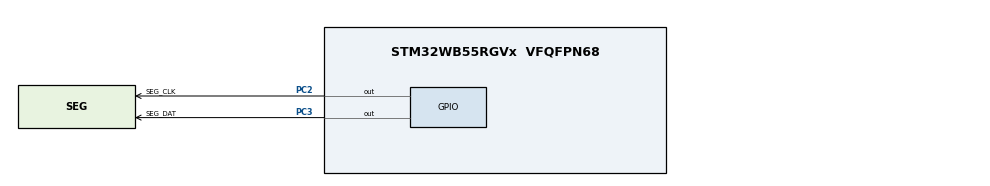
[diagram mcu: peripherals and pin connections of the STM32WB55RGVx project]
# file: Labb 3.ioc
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Mcu.Family=STM32WB
PC2.Signal=GPIO_Output
PC2.GPIO_Speed=GPIO_SPEED_FREQ_VERY_HIGH
PC3.GPIO_Speed=GPIO_SPEED_FREQ_VERY_HIGH
ProjectManager.StackSize=0x400
PC3.PinState=GPIO_PIN_SET
TIM1.Prescaler=1000
ProjectManager.TargetToolchain=STM32CubeIDE
PC3.Signal=GPIO_Output
RCC.LSE_VALUE=32768
RCC.HSE_VALUE=8000000
board=custom
RCC.VCOOutputFreq_Value=32000000
PC2.GPIO_PuPd=GPIO_PULLUP
Mcu.Name=STM32WB55RGVx
VP_TIM1_VS_ClockSourceINT.Mode=Internal
RCC.APB3Freq_Value=16000000
Mcu.Package=VFQFPN68
PC2.PinState=GPIO_PIN_SET
ProjectManager.HeapSize=0x200
RCC.HSI_VALUE=16000000
NVIC.TIM1_UP_TIM16_IRQn=true\:0\:0\:false\:false\:true\:true\:true
NVIC.PriorityGroup=NVIC_PRIORITYGROUP_4
PC2.GPIO_ModeDefaultOutputPP=GPIO_MODE_OUTPUT_OD
PC3.GPIO_Label=SEG_DAT
TIM1.Period=3200
PC3.GPIO_ModeDefaultOutputPP=GPIO_MODE_OUTPUT_OD
PC2.GPIO_Label=SEG_CLK
RCC.HSI48_VALUE=48000000
PC3.GPIO_PuPd=GPIO_PULLUP

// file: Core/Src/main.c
/* USER CODE BEGIN Header */
/**
 ******************************************************************************
 * @file           : main.c
 * @brief          : Main program body
 ******************************************************************************
 * @attention
 *
 * <h2><center>&copy; Copyright (c) 2021 STMicroelectronics.
 * All rights reserved.</center></h2>
 *
 * This software component is licensed by ST under BSD 3-Clause license,
 * the "License"; You may not use this file except in compliance with the
 * License. You may obtain a copy of the License at:
 *                        opensource.org/licenses/BSD-3-Clause
 *
 ******************************************************************************
 */
/* USER CODE END Header */
#include "main.h"
#include "SevenSeg.h"

TIM_HandleTypeDef htim1;

/* USER CODE BEGIN PV */
static int sec1;
static int sec10;
static int min1;
static int min10;
/* USER CODE END PV */

void SystemClock_Config(void);
static void MX_GPIO_Init(void);
static void MX_TIM1_Init(void);

/* USER CODE BEGIN 0 */

void HAL_TIM_PeriodElapsedCallback(TIM_HandleTypeDef *htim){
	if(htim->Instance==TIM1){
		if(++sec1>9){
			sec1=0;
			sec10++;
		}
		if(sec10 > 5){
			min1++;
			sec10 = 0;
		}
		if(min1 > 9)
		{
			min10++;
			min1=0;
		}
		if(min10>5)
			min10=0;

	}

}
/* USER CODE END 0 */

int main(void)
{

  /* MCU Configuration--------------------------------------------------------*/

  /* Reset of all peripherals, Initializes the Flash interface and the Systick. */
  HAL_Init();

  /* Configure the system clock */
  SystemClock_Config();

  /* Initialize all configured peripherals */
  MX_GPIO_Init();
  MX_TIM1_Init();
  /* USER CODE BEGIN 2 */
	HAL_TIM_Base_Start_IT(&htim1);
  /* USER CODE END 2 */

  /* Infinite loop */
  /* USER CODE BEGIN WHILE */
	while (1)
	{
		DisplayDigits(2,4,5,6,1);
		//DisplayDigits(min10, min1, sec10, sec1, sec1%2==0);
    /* USER CODE END WHILE */

	}
}

void SystemClock_Config(void)
{
  RCC_OscInitTypeDef RCC_OscInitStruct = {0};
  RCC_ClkInitTypeDef RCC_ClkInitStruct = {0};
  RCC_PeriphCLKInitTypeDef PeriphClkInitStruct = {0};

  /** Configure the main internal regulator output voltage
  */
  __HAL_PWR_VOLTAGESCALING_CONFIG(PWR_REGULATOR_VOLTAGE_SCALE1);
  /** Initializes the RCC Oscillators according to the specified parameters
  * in the RCC_OscInitTypeDef structure.
  */
  RCC_OscInitStruct.OscillatorType = RCC_OSCILLATORTYPE_HSI|RCC_OSCILLATORTYPE_MSI;
  RCC_OscInitStruct.HSIState = RCC_HSI_ON;
  RCC_OscInitStruct.MSIState = RCC_MSI_ON;
  RCC_OscInitStruct.HSICalibrationValue = RCC_HSICALIBRATION_DEFAULT;
  RCC_OscInitStruct.MSICalibrationValue = RCC_MSICALIBRATION_DEFAULT;
  RCC_OscInitStruct.MSIClockRange = RCC_MSIRANGE_6;
  RCC_OscInitStruct.PLL.PLLState = RCC_PLL_NONE;
  if (HAL_RCC_OscConfig(&RCC_OscInitStruct) != HAL_OK)
  {
    Error_Handler();
  }
  /** Configure the SYSCLKSource, HCLK, PCLK1 and PCLK2 clocks dividers
  */
  RCC_ClkInitStruct.ClockType = RCC_CLOCKTYPE_HCLK4|RCC_CLOCKTYPE_HCLK2
                              |RCC_CLOCKTYPE_HCLK|RCC_CLOCKTYPE_SYSCLK
                              |RCC_CLOCKTYPE_PCLK1|RCC_CLOCKTYPE_PCLK2;
  RCC_ClkInitStruct.SYSCLKSource = RCC_SYSCLKSOURCE_MSI;
  RCC_ClkInitStruct.AHBCLKDivider = RCC_SYSCLK_DIV1;
  RCC_ClkInitStruct.APB1CLKDivider = RCC_HCLK_DIV1;
  RCC_ClkInitStruct.APB2CLKDivider = RCC_HCLK_DIV1;
  RCC_ClkInitStruct.AHBCLK2Divider = RCC_SYSCLK_DIV1;
  RCC_ClkInitStruct.AHBCLK4Divider = RCC_SYSCLK_DIV1;

  if (HAL_RCC_ClockConfig(&RCC_ClkInitStruct, FLASH_LATENCY_0) != HAL_OK)
  {
    Error_Handler();
  }
  /** Initializes the peripherals clocks
  */
  PeriphClkInitStruct.PeriphClockSelection = RCC_PERIPHCLK_SMPS;
  PeriphClkInitStruct.SmpsClockSelection = RCC_SMPSCLKSOURCE_HSI;
  PeriphClkInitStruct.SmpsDivSelection = RCC_SMPSCLKDIV_RANGE1;
  if (HAL_RCCEx_PeriphCLKConfig(&PeriphClkInitStruct) != HAL_OK)
  {
    Error_Handler();
  }
}

static void MX_TIM1_Init(void)
{

  TIM_ClockConfigTypeDef sClockSourceConfig = {0};
  TIM_MasterConfigTypeDef sMasterConfig = {0};

  htim1.Instance = TIM1;
  htim1.Init.Prescaler = 1000;
  htim1.Init.CounterMode = TIM_COUNTERMODE_UP;
  htim1.Init.Period = 3200;
  htim1.Init.ClockDivision = TIM_CLOCKDIVISION_DIV1;
  htim1.Init.RepetitionCounter = 0;
  htim1.Init.AutoReloadPreload = TIM_AUTORELOAD_PRELOAD_DISABLE;
  if (HAL_TIM_Base_Init(&htim1) != HAL_OK)
  {
    Error_Handler();
  }
  sClockSourceConfig.ClockSource = TIM_CLOCKSOURCE_INTERNAL;
  if (HAL_TIM_ConfigClockSource(&htim1, &sClockSourceConfig) != HAL_OK)
  {
    Error_Handler();
  }
  sMasterConfig.MasterOutputTrigger = TIM_TRGO_RESET;
  sMasterConfig.MasterOutputTrigger2 = TIM_TRGO2_RESET;
  sMasterConfig.MasterSlaveMode = TIM_MASTERSLAVEMODE_DISABLE;
  if (HAL_TIMEx_MasterConfigSynchronization(&htim1, &sMasterConfig) != HAL_OK)
  {
    Error_Handler();
  }

}

static void MX_GPIO_Init(void)
{
  GPIO_InitTypeDef GPIO_InitStruct = {0};

  /* GPIO Ports Clock Enable */
  __HAL_RCC_GPIOC_CLK_ENABLE();

  /*Configure GPIO pin Output Level */
  HAL_GPIO_WritePin(GPIOC, SEG_CLK_Pin|SEG_DAT_Pin, GPIO_PIN_SET);

  /*Configure GPIO pins : SEG_CLK_Pin SEG_DAT_Pin */
  GPIO_InitStruct.Pin = SEG_CLK_Pin|SEG_DAT_Pin;
  GPIO_InitStruct.Mode = GPIO_MODE_OUTPUT_OD;
  GPIO_InitStruct.Pull = GPIO_PULLUP;
  GPIO_InitStruct.Speed = GPIO_SPEED_FREQ_VERY_HIGH;
  HAL_GPIO_Init(GPIOC, &GPIO_InitStruct);

}

void Error_Handler(void)
{
	__disable_irq();
	while (1)
	{
	}
}

/************************ (C) COPYRIGHT STMicroelectronics *****END OF FILE****/
